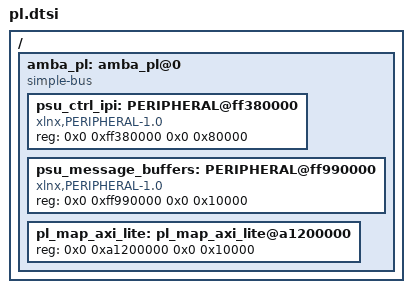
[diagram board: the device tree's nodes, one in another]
/*
 * CAUTION: This file is automatically generated by Xilinx.
 * Version: XSCT 2018.3.1
 * Today is: Tue Jul 21 11:56:55 2020
 */


/ {
	amba_pl: amba_pl@0 {
		#address-cells = <2>;
		#size-cells = <2>;
		compatible = "simple-bus";
		ranges ;
		psu_ctrl_ipi: PERIPHERAL@ff380000 {
			/* This is a place holder node for a custom IP, user may need to update the entries */
			compatible = "xlnx,PERIPHERAL-1.0";
			reg = <0x0 0xff380000 0x0 0x80000>;
		};
		psu_message_buffers: PERIPHERAL@ff990000 {
			/* This is a place holder node for a custom IP, user may need to update the entries */
			compatible = "xlnx,PERIPHERAL-1.0";
			reg = <0x0 0xff990000 0x0 0x10000>;
		};
		pl_map_axi_lite: pl_map_axi_lite@a1200000 {
			/* This is a external AXI interface, user may need to update the entries */
			reg = <0x0 0xa1200000 0x0 0x10000>;
		};
	};
};
